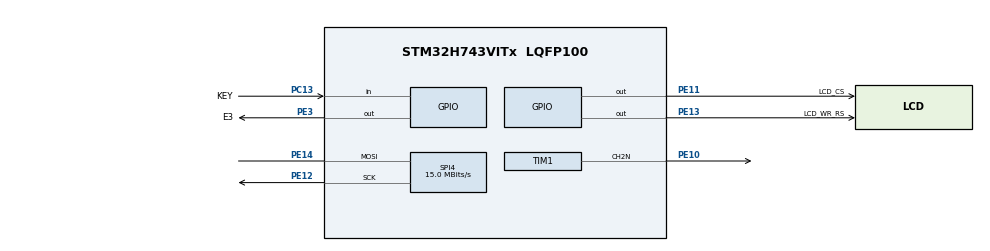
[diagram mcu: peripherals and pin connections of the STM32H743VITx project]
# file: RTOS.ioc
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FREERTOS.Tasks01=defaultTask,0,128,StartDefaultTask,Default,NULL,Dynamic,NULL,NULL
Mcu.Family=STM32H7
Mcu.Name=STM32H743VITx
Mcu.Package=LQFP100
NVIC.PriorityGroup=NVIC_PRIORITYGROUP_4
NVIC.TIM6_DAC_IRQn=true\:15\:0\:false\:false\:true\:false\:false\:true\:true
NVIC.TimeBase=TIM6_DAC_IRQn
NVIC.TimeBaseIP=TIM6
PA13\ (JTMS/SWDIO).Mode=Serial_Wire
PA13\ (JTMS/SWDIO).Signal=DEBUG_JTMS-SWDIO
PA14\ (JTCK/SWCLK).Mode=Serial_Wire
PA14\ (JTCK/SWCLK).Signal=DEBUG_JTCK-SWCLK
PC13.GPIO_Label=KEY
PC13.GPIO_PuPd=GPIO_PULLDOWN
PC13.Signal=GPIO_Input
PC14-OSC32_IN\ (OSC32_IN).Mode=LSE-External-Oscillator
PC14-OSC32_IN\ (OSC32_IN).Signal=RCC_OSC32_IN
PC15-OSC32_OUT\ (OSC32_OUT).Mode=LSE-External-Oscillator
PC15-OSC32_OUT\ (OSC32_OUT).Signal=RCC_OSC32_OUT
PE10.Mode=PWM Generation2 CH2N
PE10.Signal=TIM1_CH2N
PE11.GPIO_Label=LCD_CS
PE11.GPIO_Speed=GPIO_SPEED_FREQ_VERY_HIGH
PE11.PinState=GPIO_PIN_SET
PE11.Signal=GPIO_Output
PE12.Mode=Simplex_Bidirectional_Master
PE12.Signal=SPI4_SCK
PE13.GPIO_Label=LCD_WR_RS
PE13.GPIO_Speed=GPIO_SPEED_FREQ_VERY_HIGH
PE13.PinState=GPIO_PIN_SET
PE13.Signal=GPIO_Output
PE14.Mode=Simplex_Bidirectional_Master
PE14.Signal=SPI4_MOSI
PE3.GPIO_Label=E3
PE3.Signal=GPIO_Output
PH0-OSC_IN\ (PH0).Mode=HSE-External-Oscillator
PH0-OSC_IN\ (PH0).Signal=RCC_OSC_IN
PH1-OSC_OUT\ (PH1).Mode=HSE-External-Oscillator
PH1-OSC_OUT\ (PH1).Signal=RCC_OSC_OUT
ProjectManager.HeapSize=0x200
ProjectManager.StackSize=0x400
ProjectManager.TargetToolchain=MDK-ARM V5.32
RCC.ADCFreq_Value=129000000
RCC.APB1Freq_Value=120000000
RCC.APB2Freq_Value=120000000
RCC.APB3Freq_Value=120000000
RCC.APB4Freq_Value=120000000
RCC.CortexFreq_Value=480000000
RCC.D1PPRE=RCC_APB3_DIV2
RCC.D2PPRE1=RCC_APB1_DIV2
RCC.D2PPRE2=RCC_APB2_DIV2
RCC.D3PPRE=RCC_APB4_DIV2
RCC.DIVM1=4
RCC.DIVN1=60
RCC.HCLKFreq_Value=240000000
RCC.HPRE=RCC_HCLK_DIV2
RCC.PLL2FRACN=0
RCC.PLL3FRACN=0
RCC.PLLFRACN=0
RCC.SYSCLKFreq_VALUE=480000000
RCC.SYSCLKSource=RCC_SYSCLKSOURCE_PLLCLK
RCC.USBFreq_Value=480000000
SPI4.BaudRatePrescaler=SPI_BAUDRATEPRESCALER_8
SPI4.CalculateBaudRate=15.0 MBits/s
SPI4.DataSize=SPI_DATASIZE_8BIT
SPI4.Direction=SPI_DIRECTION_1LINE
SPI4.Mode=SPI_MODE_MASTER
SPI4.VirtualType=VM_MASTER
TIM1.Channel-PWM\ Generation2\ CH2N=TIM_CHANNEL_2
TIM1.OCNPolarity_2=TIM_OCNPOLARITY_LOW
TIM1.Period=1000-1
TIM1.Prescaler=12-1
TIM1.Pulse-PWM\ Generation2\ CH2N=500
VP_FREERTOS_VS_CMSIS_V1.Mode=CMSIS_V1
VP_SYS_VS_tim6.Mode=TIM6
VP_TIM1_VS_ClockSourceINT.Mode=Internal
board=custom

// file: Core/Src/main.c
/* USER CODE BEGIN Header */
/**
  ******************************************************************************
  * @file           : main.c
  * @brief          : Main program body
  ******************************************************************************
  * @attention
  *
  * Copyright (c) 2024 STMicroelectronics.
  * All rights reserved.
  *
  * This software is licensed under terms that can be found in the LICENSE file
  * in the root directory of this software component.
  * If no LICENSE file comes with this software, it is provided AS-IS.
  *
  ******************************************************************************
  */
/* USER CODE END Header */
#include "main.h"
#include "cmsis_os.h"
#include "spi.h"
#include "tim.h"
#include "gpio.h"

/* USER CODE BEGIN Includes */
#include "st7735.h"
#include "lcd.h"
/* USER CODE END Includes */

void SystemClock_Config(void);
void MX_FREERTOS_Init(void);

int main(void)
{

  /* MCU Configuration--------------------------------------------------------*/

  /* Reset of all peripherals, Initializes the Flash interface and the Systick. */
  HAL_Init();

  /* Configure the system clock */
  SystemClock_Config();

  /* Initialize all configured peripherals */
  MX_GPIO_Init();
  MX_SPI4_Init();
  MX_TIM1_Init();
  /* USER CODE BEGIN 2 */
	HAL_TIMEx_PWMN_Start(&htim1,TIM_CHANNEL_2);
	__HAL_TIM_SetCompare(&htim1, TIM_CHANNEL_2, 900);
	LCD_Test();

  /* USER CODE END 2 */

  /* Call init function for freertos objects (in freertos.c) */
  MX_FREERTOS_Init();

  /* Start scheduler */
  osKernelStart();

  /* We should never get here as control is now taken by the scheduler */
  /* Infinite loop */
  while (1)
  {

  }
}

void SystemClock_Config(void)
{
  RCC_OscInitTypeDef RCC_OscInitStruct = {0};
  RCC_ClkInitTypeDef RCC_ClkInitStruct = {0};

  /** Supply configuration update enable
  */
  HAL_PWREx_ConfigSupply(PWR_LDO_SUPPLY);

  /** Configure the main internal regulator output voltage
  */
  __HAL_PWR_VOLTAGESCALING_CONFIG(PWR_REGULATOR_VOLTAGE_SCALE1);

  while(!__HAL_PWR_GET_FLAG(PWR_FLAG_VOSRDY)) {}

  __HAL_RCC_SYSCFG_CLK_ENABLE();
  __HAL_PWR_VOLTAGESCALING_CONFIG(PWR_REGULATOR_VOLTAGE_SCALE0);

  while(!__HAL_PWR_GET_FLAG(PWR_FLAG_VOSRDY)) {}

  /** Initializes the RCC Oscillators according to the specified parameters
  * in the RCC_OscInitTypeDef structure.
  */
  RCC_OscInitStruct.OscillatorType = RCC_OSCILLATORTYPE_HSI;
  RCC_OscInitStruct.HSIState = RCC_HSI_DIV1;
  RCC_OscInitStruct.HSICalibrationValue = RCC_HSICALIBRATION_DEFAULT;
  RCC_OscInitStruct.PLL.PLLState = RCC_PLL_ON;
  RCC_OscInitStruct.PLL.PLLSource = RCC_PLLSOURCE_HSI;
  RCC_OscInitStruct.PLL.PLLM = 4;
  RCC_OscInitStruct.PLL.PLLN = 60;
  RCC_OscInitStruct.PLL.PLLP = 2;
  RCC_OscInitStruct.PLL.PLLQ = 2;
  RCC_OscInitStruct.PLL.PLLR = 2;
  RCC_OscInitStruct.PLL.PLLRGE = RCC_PLL1VCIRANGE_3;
  RCC_OscInitStruct.PLL.PLLVCOSEL = RCC_PLL1VCOWIDE;
  RCC_OscInitStruct.PLL.PLLFRACN = 0;
  if (HAL_RCC_OscConfig(&RCC_OscInitStruct) != HAL_OK)
  {
    Error_Handler();
  }

  /** Initializes the CPU, AHB and APB buses clocks
  */
  RCC_ClkInitStruct.ClockType = RCC_CLOCKTYPE_HCLK|RCC_CLOCKTYPE_SYSCLK
                              |RCC_CLOCKTYPE_PCLK1|RCC_CLOCKTYPE_PCLK2
                              |RCC_CLOCKTYPE_D3PCLK1|RCC_CLOCKTYPE_D1PCLK1;
  RCC_ClkInitStruct.SYSCLKSource = RCC_SYSCLKSOURCE_PLLCLK;
  RCC_ClkInitStruct.SYSCLKDivider = RCC_SYSCLK_DIV1;
  RCC_ClkInitStruct.AHBCLKDivider = RCC_HCLK_DIV2;
  RCC_ClkInitStruct.APB3CLKDivider = RCC_APB3_DIV2;
  RCC_ClkInitStruct.APB1CLKDivider = RCC_APB1_DIV2;
  RCC_ClkInitStruct.APB2CLKDivider = RCC_APB2_DIV2;
  RCC_ClkInitStruct.APB4CLKDivider = RCC_APB4_DIV2;

  if (HAL_RCC_ClockConfig(&RCC_ClkInitStruct, FLASH_LATENCY_4) != HAL_OK)
  {
    Error_Handler();
  }
}

void HAL_TIM_PeriodElapsedCallback(TIM_HandleTypeDef *htim)
{
  if (htim->Instance == TIM6) {
    HAL_IncTick();
  }
}

void Error_Handler(void)
{
  __disable_irq();
  while (1)
  {
  }
}

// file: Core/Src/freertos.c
/* USER CODE BEGIN Header */
/**
  ******************************************************************************
  * File Name          : freertos.c
  * Description        : Code for freertos applications
  ******************************************************************************
  * @attention
  *
  * Copyright (c) 2024 STMicroelectronics.
  * All rights reserved.
  *
  * This software is licensed under terms that can be found in the LICENSE file
  * in the root directory of this software component.
  * If no LICENSE file comes with this software, it is provided AS-IS.
  *
  ******************************************************************************
  */
/* USER CODE END Header */

#include "FreeRTOS.h"
#include "task.h"
#include "main.h"
#include "cmsis_os.h"

osThreadId defaultTaskHandle;

void StartDefaultTask(void const * argument);

void MX_FREERTOS_Init(void); /* (MISRA C 2004 rule 8.1) */

/* GetIdleTaskMemory prototype (linked to static allocation support) */
void vApplicationGetIdleTaskMemory( StaticTask_t **ppxIdleTaskTCBBuffer, StackType_t **ppxIdleTaskStackBuffer, uint32_t *pulIdleTaskStackSize );

/* USER CODE BEGIN GET_IDLE_TASK_MEMORY */
static StaticTask_t xIdleTaskTCBBuffer;
static StackType_t xIdleStack[configMINIMAL_STACK_SIZE];

void vApplicationGetIdleTaskMemory( StaticTask_t **ppxIdleTaskTCBBuffer, StackType_t **ppxIdleTaskStackBuffer, uint32_t *pulIdleTaskStackSize )
{
  *ppxIdleTaskTCBBuffer = &xIdleTaskTCBBuffer;
  *ppxIdleTaskStackBuffer = &xIdleStack[0];
  *pulIdleTaskStackSize = configMINIMAL_STACK_SIZE;
  /* place for user code */
}
/* USER CODE END GET_IDLE_TASK_MEMORY */

void MX_FREERTOS_Init(void) {

  /* Create the thread(s) */
  /* definition and creation of defaultTask */
  osThreadDef(defaultTask, StartDefaultTask, osPriorityNormal, 0, 128);
  defaultTaskHandle = osThreadCreate(osThread(defaultTask), NULL);

}

void StartDefaultTask(void const * argument)
{
  /* USER CODE BEGIN StartDefaultTask */
  /* Infinite loop */
  for(;;)
  {
		HAL_GPIO_TogglePin(GPIOE,GPIO_PIN_3);
    osDelay(1000);
  }
  /* USER CODE END StartDefaultTask */
}
